# ZB204 register map
Vendor: GS; File version: 1.2
CPU: CM3 r2p0, little endian, MPU, no FPU, VTOR, 3 interrupt priority bits
Registers are 32-bit, read-write, reset 0x0 unless marked. A register's access mark holds for its fields unless they carry their own. Offsets are from the block's base; [hi:lo] are bit positions; {n}, {i} and the like mark numbered series.

## PWM0 — Pulse Width Modulator
Base 0x40A00000
Same registers: PWM1 0x40B00000
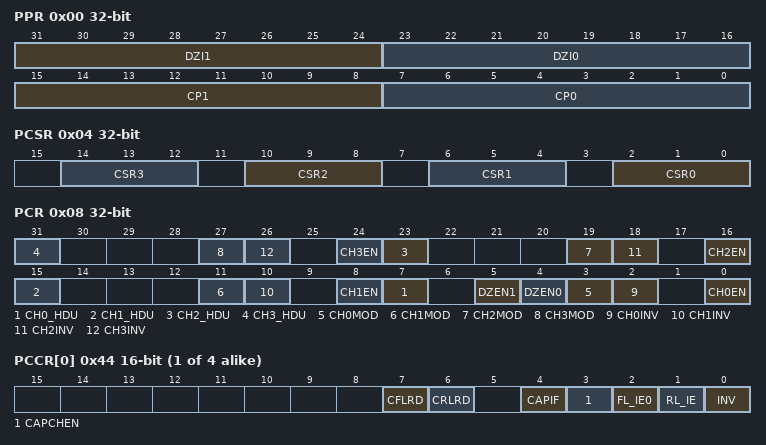
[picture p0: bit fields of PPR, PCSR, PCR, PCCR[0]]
0x00 PPR — PWM Pre-scale Register
  [31:24] DZI1 — Dead zone interval register 1 for PWM2 and PWM3
  [23:16] DZI0 — Dead zone interval register 0 for PWM0 and PWM1
  [15:8] CP1 — Clock pre-scale 1 for PWM Timer 2,3
  [7:0] CP0 — Clock pre-scale 0 for PWM Timer 0,1
0x04 PCSR — PWM Clock Select Register
  [4n+2:4n] CSR{n} (n=0..3) — Timer Clock Source Selection
0x08 PCR — PWM Control Register
  [8n+7] CH{n}_HDU (n=0..3) — Timer{n} Half cycle add Enable/Disable
    0=Disable; 1=Enable
  [8n+3] CH{n}MOD (n=0..3) — Timer {n} Auto-load/One-Shot Mode
    0=One-Shot Mode; 1=Auto-load Mode
  [8n+2] CH{n}INV (n=0..3) — Timer {n} Inverter ON/OFF
    0=OFF; 1=ON
  [8n] CH{n}EN (n=0..3) — Timer {n} Enable/Disable
    0=Disable; 1=Enable
  [5] DZEN1 — Dead-Zone 1 Generator Enable/Disable
    0=Disable; 1=Enable
  [4] DZEN0 — Dead-Zone 0 Generator Enable/Disable
    0=Disable; 1=Enable
0x0C PCNR0 — PWM Counter Register0
  [15:0] CNR — PWM Counter/Timer Loaded Value
{0x10+0xC*i} PCMR{i} (i=0..3) — PWM Comparator Register{i}
  [15:0] CMR — PWM Comparator Register
{0x14+0xC*i} PTR{i} (i=0..3) — PWM Timer Register{i}
  [15:0] CTR — PWM Timer value
0x18 PCNR1 — PWM Timer Register0
  [15:0] CNR — PWM Counter/Timer Loaded Value
0x24 PCNR2 — PWM Counter Register2
  [15:0] CNR — PWM Counter/Timer Loaded Value
0x30 PCNR3 — PWM Counter Register3
  [15:0] CNR — PWM Counter/Timer Loaded Value
0x3C PIER — PWM Interrupt Enable Register
  [3:0] PIER — PWM Timer Interrupt Enable
0x40 PIFR — PWM Interrupt FlagRegister
  [3:0] PIFR — PWM Timer Interrupt Flag
{0x44+2i} PCCR[{i}] (i=0..3) 16-bit — PWM Capture Control Register
  [7] CFLRD — Capture Falling Latch Register load flag
    0=Disable; 1=Enable
  [6] CRLRD — Capture Rising Latch Register load flag
    0=Disable; 1=Enable
  [4] CAPIF — Capture Channel x interrupt flag
    0=Disable; 1=Enable
  [3] CAPCHEN — Capture Channel x Enable/Disable
    0=Disable; 1=Enable
  [2] FL_IE0 — Channel x Falling Interrupt Enable ON/OFF
    0=OFF; 1=ON
  [1] RL_IE — Channel x Falling Interrupt Enable ON/OFF
    0=OFF; 1=ON
  [0] INV — Channel x Inverter ON/OFF
    0=OFF; 1=ON
{0x4C+8i} PCRLR{i} (i=0..3) — PWM Capture Rising Latch Register
  [15:0] CRLR — Capture Rising Latch Registerx
{0x50+8i} PCFLR{i} (i=0..3) — PWM Capture Falling Latch Register
  [15:0] CFLR — Capture Falling Latch Registerx
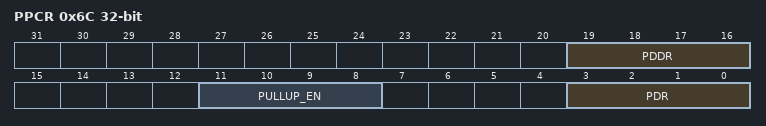
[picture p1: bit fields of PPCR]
0x6C PPCR — PWM Port Control Register
  [19:16] PDDR — Port Data Direction Register
  [11:8] PULLUP_EN — Port Pull up Enable
  [3:0] PDR — Port Data Register

## EPORT0 — Edge Port Module
Base 0x40140000
Same registers: EPORT{n} {0x40140000+0x10000*n} (n=1..9)
0x00 EPIER 8-bit — EPORT Port Interrupt Enable Register
0x01 EPDDR 8-bit — EPORT Data Direction Register
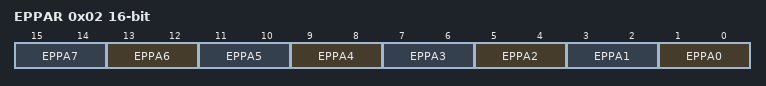
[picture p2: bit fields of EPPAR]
0x02 EPPAR 16-bit — EPORT Pin Assignment Register
  [2n+1:2n] EPPA{n} (n=0..7) — EPORT Pin Assignment Select Fields
0x04 EPLPR 8-bit — EPORT Level Polarity Register
0x05 EPFR 8-bit — EPORT Flag Register
0x06 EPPDR 8-bit — EPORT Pin Data Register
0x07 EPDR 8-bit — EPORT Data Register
0x09 EPBTR 8-bit — EPORT Bit Toggle Register
0x0A EPBCR 8-bit — EPORT Bit Clear Register
0x0B EPBSR 8-bit — EPORT Bit Set Register
0x0F EPLFR 8-bit — EPORT inter

## PORTS — Port Configuration
Base 0x40040000
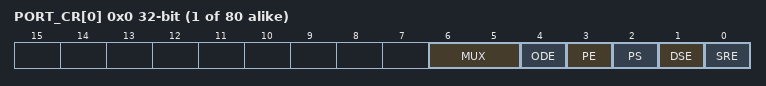
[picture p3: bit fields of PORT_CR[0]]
{0x0+4i} PORT_CR[{i}] (i=0..79) — PORT Configure Register
  [6:5] MUX — Alternal funtion
    0=alt1; 1=alt2; 2=GPIO; 3=analog
  [4] ODE — Open drain enable
    0=Open-drain enable; 1=Open-drain disable
  [3] PE — Pull Enable
    0=Pin Pull enable; 1=Pin Pull disable
  [2] PS — Pull Select
    0=Pin Pull-down; 1=Pin Pull-up
  [1] DSE — Driver strength
    0=low level-sensitive; 1=high level-sensitive
  [0] SRE — Slow rate
    0=Slow; 1=Fast
